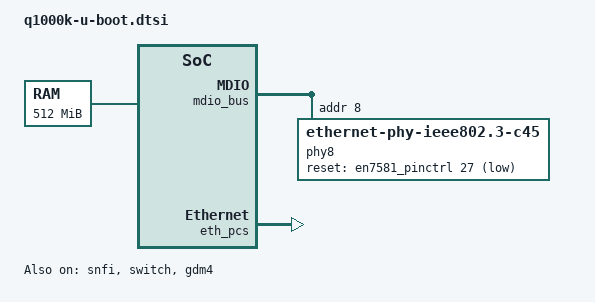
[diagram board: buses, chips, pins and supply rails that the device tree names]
// SPDX-License-Identifier: GPL-2.0+

#include "an7581-u-boot.dtsi"

/ {
	config {
		/* Never attach UBI while loading a saved environment. */
		load-environment = <0>;
	};

	memory@80000000 {
		device_type = "memory";
		reg = <0x0 0x80000000 0x0 0x20000000>;
	};

	/* Q1000K routes its sole external RTL8261 through Ethernet SerDes. */
	mdio_bus: mdio-bus {
		compatible = "airoha,arht-mdio";
		#address-cells = <1>;
		#size-cells = <0>;

		phy8: ethernet-phy@8 {
			compatible = "ethernet-phy-ieee802.3-c45";
			reg = <8>;
			reset-gpios = <&en7581_pinctrl 27 GPIO_ACTIVE_LOW>;
			reset-assert-us = <200000>;
			reset-deassert-us = <200000>;
		};
	};
};

&snfi {
	status = "okay";
};

&eth_pcs {
	status = "okay";
};

&switch {
	status = "okay";
	pinctrl-names = "default";
	pinctrl-0 = <&mdio_pins>;
	airoha,phy-poll-start = <8>;
	airoha,phy-poll-end = <8>;
	airoha,recovery-phy-mask = <0x100>;
};

&gdm4 {
	status = "okay";
	phy-mode = "usxgmii";
	phy-handle = <&phy8>;
	pcs = <&eth_pcs>;
	airoha,source-port = <0x18>;
	airoha,tx-channel = <13>;
};
